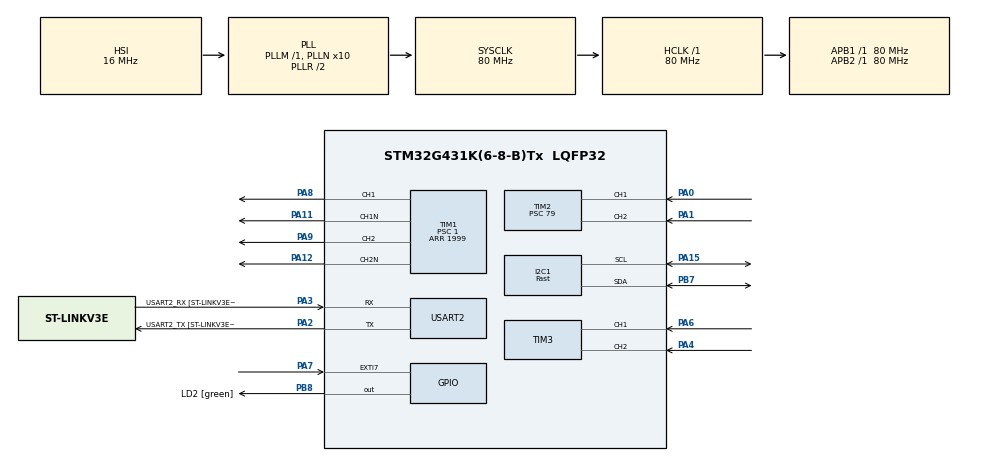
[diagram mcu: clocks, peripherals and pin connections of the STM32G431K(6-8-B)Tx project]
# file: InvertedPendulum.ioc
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I2C1.CustomTiming=Disabled
I2C1.I2C_Speed_Mode=I2C_Fast
I2C1.Timing=0x00702991
Mcu.Family=STM32G4
Mcu.Name=STM32G431K(6-8-B)Tx
Mcu.Package=LQFP32
NVIC.EXTI9_5_IRQn=true\:0\:0\:false\:false\:true\:true\:true\:true
NVIC.PriorityGroup=NVIC_PRIORITYGROUP_4
NVIC.TIM1_TRG_COM_TIM17_IRQn=true\:0\:0\:false\:false\:true\:true\:true\:true
NVIC.TIM1_UP_TIM16_IRQn=true\:0\:0\:false\:false\:true\:true\:true\:true
PA0.Signal=S_TIM2_CH1
PA1.Signal=S_TIM2_CH2
PA11.Mode=PWM Generation1 CH1 CH1N
PA11.Signal=TIM1_CH1N
PA12.Mode=PWM Generation2 CH2 CH2N
PA12.Signal=TIM1_CH2N
PA13.GPIO_Label=T_SWDIO
PA13.Mode=Serial_Wire
PA13.Signal=SYS_JTMS-SWDIO
PA14.GPIO_Label=T_SWCLK
PA14.Mode=Serial_Wire
PA14.Signal=SYS_JTCK-SWCLK
PA15.Mode=I2C
PA15.Signal=I2C1_SCL
PA2.GPIO_Label=USART2_TX [ST-LINKV3E_VCP_RX]
PA2.Mode=Asynchronous
PA2.Signal=USART2_TX
PA3.GPIO_Label=USART2_RX [ST-LINKV3E_VCP_TX]
PA3.Mode=Asynchronous
PA3.Signal=USART2_RX
PA4.Signal=S_TIM3_CH2
PA6.Signal=S_TIM3_CH1
PA7.Signal=GPXTI7
PA8.Signal=S_TIM1_CH1
PA9.Signal=S_TIM1_CH2
PB7.Mode=I2C
PB7.Signal=I2C1_SDA
PB8-BOOT0.GPIO_Label=LD2 [green]
PB8-BOOT0.Signal=GPIO_Output
ProjectManager.HeapSize=0x200
ProjectManager.StackSize=0x400
ProjectManager.TargetToolchain=STM32CubeIDE
RCC.ADC12Freq_Value=80000000
RCC.AHBFreq_Value=80000000
RCC.APB1Freq_Value=80000000
RCC.APB1TimFreq_Value=80000000
RCC.APB2Freq_Value=80000000
RCC.APB2TimFreq_Value=80000000
RCC.CortexFreq_Value=80000000
RCC.EXTERNAL_CLOCK_VALUE=12288000
RCC.HCLKFreq_Value=80000000
RCC.HSE_VALUE=8000000
RCC.HSI48_VALUE=48000000
RCC.HSI_VALUE=16000000
RCC.LSE_VALUE=32768
RCC.PLLN=10
RCC.SYSCLKFreq_VALUE=80000000
RCC.SYSCLKSource=RCC_SYSCLKSOURCE_PLLCLK
RCC.USBFreq_Value=80000000
RCC.VCOOutputFreq_Value=160000000
SH.S_TIM1_CH1.0=TIM1_CH1,PWM Generation1 CH1 CH1N
SH.S_TIM1_CH2.0=TIM1_CH2,PWM Generation2 CH2 CH2N
SH.S_TIM2_CH1.0=TIM2_CH1,Encoder_Interface
SH.S_TIM2_CH2.0=TIM2_CH2,Encoder_Interface
SH.S_TIM3_CH1.0=TIM3_CH1,Encoder_Interface
SH.S_TIM3_CH2.0=TIM3_CH2,Encoder_Interface
TIM1.AsymmetricalDeadTime=ENABLE
TIM1.Channel-PWM\ Generation1\ CH1\ CH1N=TIM_CHANNEL_1
TIM1.Channel-PWM\ Generation2\ CH2\ CH2N=TIM_CHANNEL_2
TIM1.FallingDeadTime=5
TIM1.OCMode_PWM-PWM\ Generation1\ CH1\ CH1N=TIM_OCMODE_ASSYMETRIC_PWM1
TIM1.OCMode_PWM-PWM\ Generation2\ CH2\ CH2N=TIM_OCMODE_ASSYMETRIC_PWM1
TIM1.PeriodNoDither=1999
TIM1.Prescaler=1
TIM16.PeriodNoDither=999
TIM16.Prescaler=799
TIM17.PeriodNoDither=999
TIM17.Prescaler=79
TIM2.EncoderMode=TIM_ENCODERMODE_TI12
TIM2.PeriodNoDither=999
TIM2.Prescaler=79
TIM3.EncoderMode=TIM_ENCODERMODE_TI12
USART2.VirtualMode-Asynchronous=VM_ASYNC
USART2.WordLength=WORDLENGTH_8B
VP_TIM16_VS_ClockSourceINT.Mode=Enable_Timer
VP_TIM17_VS_ClockSourceINT.Mode=Enable_Timer
VP_TIM1_VS_ClockSourceINT.Mode=Internal
board=NUCLEO-G431KB

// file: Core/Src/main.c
/* USER CODE BEGIN Header */
/**
  ******************************************************************************
  * @file           : main.c
  * @brief          : Main program body
  ******************************************************************************
  * @attention
  *
  * Copyright (c) 2023 STMicroelectronics.
  * All rights reserved.
  *
  * This software is licensed under terms that can be found in the LICENSE file
  * in the root directory of this software component.
  * If no LICENSE file comes with this software, it is provided AS-IS.
  *
  ******************************************************************************
  */
/* USER CODE END Header */
#include "main.h"

/* USER CODE BEGIN Includes */
#include <stdio.h>

/* USER CODE END Includes */

I2C_HandleTypeDef hi2c1;

TIM_HandleTypeDef htim1;
TIM_HandleTypeDef htim2;
TIM_HandleTypeDef htim3;
TIM_HandleTypeDef htim16;
TIM_HandleTypeDef htim17;

UART_HandleTypeDef huart2;

void SystemClock_Config(void);
static void MX_GPIO_Init(void);
static void MX_USART2_UART_Init(void);
static void MX_TIM2_Init(void);
static void MX_TIM3_Init(void);
static void MX_TIM1_Init(void);
static void MX_TIM17_Init(void);
static void MX_I2C1_Init(void);
static void MX_TIM16_Init(void);

/* USER CODE BEGIN 0 */
int _write(int file, char *ptr, int len)
{
	HAL_UART_Transmit(&huart2, (uint8_t *)ptr, len, 10);
	return len;
}

int16_t read_encoder_value(TIM_TypeDef TIM)
{
	uint16_t enc_buff = TIM->CNT;
	TIM->CNT = 0;
	return (int16_t)enc_buff;
}

/* USER CODE END 0 */

int main(void)
{

  /* MCU Configuration--------------------------------------------------------*/

  /* Reset of all peripherals, Initializes the Flash interface and the Systick. */
  HAL_Init();

  /* Configure the system clock */
  SystemClock_Config();

  /* Initialize all configured peripherals */
  MX_GPIO_Init();
  MX_USART2_UART_Init();
  MX_TIM2_Init();
  MX_TIM3_Init();
  MX_TIM1_Init();
  MX_TIM17_Init();
  MX_I2C1_Init();
  MX_TIM16_Init();

  /* Infinite loop */
  while (1)
  {

  }
}

void SystemClock_Config(void)
{
  RCC_OscInitTypeDef RCC_OscInitStruct = {0};
  RCC_ClkInitTypeDef RCC_ClkInitStruct = {0};

  /** Configure the main internal regulator output voltage
  */
  HAL_PWREx_ControlVoltageScaling(PWR_REGULATOR_VOLTAGE_SCALE1);

  /** Initializes the RCC Oscillators according to the specified parameters
  * in the RCC_OscInitTypeDef structure.
  */
  RCC_OscInitStruct.OscillatorType = RCC_OSCILLATORTYPE_HSI;
  RCC_OscInitStruct.HSIState = RCC_HSI_ON;
  RCC_OscInitStruct.HSICalibrationValue = RCC_HSICALIBRATION_DEFAULT;
  RCC_OscInitStruct.PLL.PLLState = RCC_PLL_ON;
  RCC_OscInitStruct.PLL.PLLSource = RCC_PLLSOURCE_HSI;
  RCC_OscInitStruct.PLL.PLLM = RCC_PLLM_DIV1;
  RCC_OscInitStruct.PLL.PLLN = 10;
  RCC_OscInitStruct.PLL.PLLP = RCC_PLLP_DIV2;
  RCC_OscInitStruct.PLL.PLLQ = RCC_PLLQ_DIV2;
  RCC_OscInitStruct.PLL.PLLR = RCC_PLLR_DIV2;
  if (HAL_RCC_OscConfig(&RCC_OscInitStruct) != HAL_OK)
  {
    Error_Handler();
  }

  /** Initializes the CPU, AHB and APB buses clocks
  */
  RCC_ClkInitStruct.ClockType = RCC_CLOCKTYPE_HCLK|RCC_CLOCKTYPE_SYSCLK
                              |RCC_CLOCKTYPE_PCLK1|RCC_CLOCKTYPE_PCLK2;
  RCC_ClkInitStruct.SYSCLKSource = RCC_SYSCLKSOURCE_PLLCLK;
  RCC_ClkInitStruct.AHBCLKDivider = RCC_SYSCLK_DIV1;
  RCC_ClkInitStruct.APB1CLKDivider = RCC_HCLK_DIV1;
  RCC_ClkInitStruct.APB2CLKDivider = RCC_HCLK_DIV1;

  if (HAL_RCC_ClockConfig(&RCC_ClkInitStruct, FLASH_LATENCY_2) != HAL_OK)
  {
    Error_Handler();
  }
}

static void MX_I2C1_Init(void)
{

  hi2c1.Instance = I2C1;
  hi2c1.Init.Timing = 0x00702991;
  hi2c1.Init.OwnAddress1 = 0;
  hi2c1.Init.AddressingMode = I2C_ADDRESSINGMODE_7BIT;
  hi2c1.Init.DualAddressMode = I2C_DUALADDRESS_DISABLE;
  hi2c1.Init.OwnAddress2 = 0;
  hi2c1.Init.OwnAddress2Masks = I2C_OA2_NOMASK;
  hi2c1.Init.GeneralCallMode = I2C_GENERALCALL_DISABLE;
  hi2c1.Init.NoStretchMode = I2C_NOSTRETCH_DISABLE;
  if (HAL_I2C_Init(&hi2c1) != HAL_OK)
  {
    Error_Handler();
  }

  /** Configure Analogue filter
  */
  if (HAL_I2CEx_ConfigAnalogFilter(&hi2c1, I2C_ANALOGFILTER_ENABLE) != HAL_OK)
  {
    Error_Handler();
  }

  /** Configure Digital filter
  */
  if (HAL_I2CEx_ConfigDigitalFilter(&hi2c1, 0) != HAL_OK)
  {
    Error_Handler();
  }

}

static void MX_TIM1_Init(void)
{

  TIM_ClockConfigTypeDef sClockSourceConfig = {0};
  TIM_MasterConfigTypeDef sMasterConfig = {0};
  TIM_OC_InitTypeDef sConfigOC = {0};
  TIM_BreakDeadTimeConfigTypeDef sBreakDeadTimeConfig = {0};

  htim1.Instance = TIM1;
  htim1.Init.Prescaler = 1;
  htim1.Init.CounterMode = TIM_COUNTERMODE_UP;
  htim1.Init.Period = 1999;
  htim1.Init.ClockDivision = TIM_CLOCKDIVISION_DIV1;
  htim1.Init.RepetitionCounter = 0;
  htim1.Init.AutoReloadPreload = TIM_AUTORELOAD_PRELOAD_DISABLE;
  if (HAL_TIM_Base_Init(&htim1) != HAL_OK)
  {
    Error_Handler();
  }
  sClockSourceConfig.ClockSource = TIM_CLOCKSOURCE_INTERNAL;
  if (HAL_TIM_ConfigClockSource(&htim1, &sClockSourceConfig) != HAL_OK)
  {
    Error_Handler();
  }
  if (HAL_TIM_PWM_Init(&htim1) != HAL_OK)
  {
    Error_Handler();
  }
  sMasterConfig.MasterOutputTrigger = TIM_TRGO_RESET;
  sMasterConfig.MasterOutputTrigger2 = TIM_TRGO2_RESET;
  sMasterConfig.MasterSlaveMode = TIM_MASTERSLAVEMODE_DISABLE;
  if (HAL_TIMEx_MasterConfigSynchronization(&htim1, &sMasterConfig) != HAL_OK)
  {
    Error_Handler();
  }
  sConfigOC.OCMode = TIM_OCMODE_ASSYMETRIC_PWM1;
  sConfigOC.Pulse = 0;
  sConfigOC.OCPolarity = TIM_OCPOLARITY_HIGH;
  sConfigOC.OCNPolarity = TIM_OCNPOLARITY_HIGH;
  sConfigOC.OCFastMode = TIM_OCFAST_DISABLE;
  sConfigOC.OCIdleState = TIM_OCIDLESTATE_RESET;
  sConfigOC.OCNIdleState = TIM_OCNIDLESTATE_RESET;
  if (HAL_TIM_PWM_ConfigChannel(&htim1, &sConfigOC, TIM_CHANNEL_1) != HAL_OK)
  {
    Error_Handler();
  }
  if (HAL_TIM_PWM_ConfigChannel(&htim1, &sConfigOC, TIM_CHANNEL_2) != HAL_OK)
  {
    Error_Handler();
  }
  HAL_TIMEx_ConfigAsymmetricalDeadTime(&htim1, 5);
  HAL_TIMEx_EnableAsymmetricalDeadTime(&htim1);
  sBreakDeadTimeConfig.OffStateRunMode = TIM_OSSR_DISABLE;
  sBreakDeadTimeConfig.OffStateIDLEMode = TIM_OSSI_DISABLE;
  sBreakDeadTimeConfig.LockLevel = TIM_LOCKLEVEL_OFF;
  sBreakDeadTimeConfig.DeadTime = 0;
  sBreakDeadTimeConfig.BreakState = TIM_BREAK_DISABLE;
  sBreakDeadTimeConfig.BreakPolarity = TIM_BREAKPOLARITY_HIGH;
  sBreakDeadTimeConfig.BreakFilter = 0;
  sBreakDeadTimeConfig.BreakAFMode = TIM_BREAK_AFMODE_INPUT;
  sBreakDeadTimeConfig.Break2State = TIM_BREAK2_DISABLE;
  sBreakDeadTimeConfig.Break2Polarity = TIM_BREAK2POLARITY_HIGH;
  sBreakDeadTimeConfig.Break2Filter = 0;
  sBreakDeadTimeConfig.Break2AFMode = TIM_BREAK_AFMODE_INPUT;
  sBreakDeadTimeConfig.AutomaticOutput = TIM_AUTOMATICOUTPUT_DISABLE;
  if (HAL_TIMEx_ConfigBreakDeadTime(&htim1, &sBreakDeadTimeConfig) != HAL_OK)
  {
    Error_Handler();
  }
  HAL_TIM_MspPostInit(&htim1);

}

static void MX_TIM2_Init(void)
{

  TIM_Encoder_InitTypeDef sConfig = {0};
  TIM_MasterConfigTypeDef sMasterConfig = {0};

  htim2.Instance = TIM2;
  htim2.Init.Prescaler = 79;
  htim2.Init.CounterMode = TIM_COUNTERMODE_UP;
  htim2.Init.Period = 999;
  htim2.Init.ClockDivision = TIM_CLOCKDIVISION_DIV1;
  htim2.Init.AutoReloadPreload = TIM_AUTORELOAD_PRELOAD_DISABLE;
  sConfig.EncoderMode = TIM_ENCODERMODE_TI12;
  sConfig.IC1Polarity = TIM_ICPOLARITY_RISING;
  sConfig.IC1Selection = TIM_ICSELECTION_DIRECTTI;
  sConfig.IC1Prescaler = TIM_ICPSC_DIV1;
  sConfig.IC1Filter = 0;
  sConfig.IC2Polarity = TIM_ICPOLARITY_RISING;
  sConfig.IC2Selection = TIM_ICSELECTION_DIRECTTI;
  sConfig.IC2Prescaler = TIM_ICPSC_DIV1;
  sConfig.IC2Filter = 0;
  if (HAL_TIM_Encoder_Init(&htim2, &sConfig) != HAL_OK)
  {
    Error_Handler();
  }
  sMasterConfig.MasterOutputTrigger = TIM_TRGO_RESET;
  sMasterConfig.MasterSlaveMode = TIM_MASTERSLAVEMODE_DISABLE;
  if (HAL_TIMEx_MasterConfigSynchronization(&htim2, &sMasterConfig) != HAL_OK)
  {
    Error_Handler();
  }

}

static void MX_TIM3_Init(void)
{

  TIM_Encoder_InitTypeDef sConfig = {0};
  TIM_MasterConfigTypeDef sMasterConfig = {0};

  htim3.Instance = TIM3;
  htim3.Init.Prescaler = 0;
  htim3.Init.CounterMode = TIM_COUNTERMODE_UP;
  htim3.Init.Period = 65535;
  htim3.Init.ClockDivision = TIM_CLOCKDIVISION_DIV1;
  htim3.Init.AutoReloadPreload = TIM_AUTORELOAD_PRELOAD_DISABLE;
  sConfig.EncoderMode = TIM_ENCODERMODE_TI12;
  sConfig.IC1Polarity = TIM_ICPOLARITY_RISING;
  sConfig.IC1Selection = TIM_ICSELECTION_DIRECTTI;
  sConfig.IC1Prescaler = TIM_ICPSC_DIV1;
  sConfig.IC1Filter = 0;
  sConfig.IC2Polarity = TIM_ICPOLARITY_RISING;
  sConfig.IC2Selection = TIM_ICSELECTION_DIRECTTI;
  sConfig.IC2Prescaler = TIM_ICPSC_DIV1;
  sConfig.IC2Filter = 0;
  if (HAL_TIM_Encoder_Init(&htim3, &sConfig) != HAL_OK)
  {
    Error_Handler();
  }
  sMasterConfig.MasterOutputTrigger = TIM_TRGO_RESET;
  sMasterConfig.MasterSlaveMode = TIM_MASTERSLAVEMODE_DISABLE;
  if (HAL_TIMEx_MasterConfigSynchronization(&htim3, &sMasterConfig) != HAL_OK)
  {
    Error_Handler();
  }

}

static void MX_TIM16_Init(void)
{

  htim16.Instance = TIM16;
  htim16.Init.Prescaler = 799;
  htim16.Init.CounterMode = TIM_COUNTERMODE_UP;
  htim16.Init.Period = 999;
  htim16.Init.ClockDivision = TIM_CLOCKDIVISION_DIV1;
  htim16.Init.RepetitionCounter = 0;
  htim16.Init.AutoReloadPreload = TIM_AUTORELOAD_PRELOAD_DISABLE;
  if (HAL_TIM_Base_Init(&htim16) != HAL_OK)
  {
    Error_Handler();
  }

}

static void MX_TIM17_Init(void)
{

  htim17.Instance = TIM17;
  htim17.Init.Prescaler = 79;
  htim17.Init.CounterMode = TIM_COUNTERMODE_UP;
  htim17.Init.Period = 999;
  htim17.Init.ClockDivision = TIM_CLOCKDIVISION_DIV1;
  htim17.Init.RepetitionCounter = 0;
  htim17.Init.AutoReloadPreload = TIM_AUTORELOAD_PRELOAD_DISABLE;
  if (HAL_TIM_Base_Init(&htim17) != HAL_OK)
  {
    Error_Handler();
  }

}

static void MX_USART2_UART_Init(void)
{

  huart2.Instance = USART2;
  huart2.Init.BaudRate = 115200;
  huart2.Init.WordLength = UART_WORDLENGTH_8B;
  huart2.Init.StopBits = UART_STOPBITS_1;
  huart2.Init.Parity = UART_PARITY_NONE;
  huart2.Init.Mode = UART_MODE_TX_RX;
  huart2.Init.HwFlowCtl = UART_HWCONTROL_NONE;
  huart2.Init.OverSampling = UART_OVERSAMPLING_16;
  huart2.Init.OneBitSampling = UART_ONE_BIT_SAMPLE_DISABLE;
  huart2.Init.ClockPrescaler = UART_PRESCALER_DIV1;
  huart2.AdvancedInit.AdvFeatureInit = UART_ADVFEATURE_NO_INIT;
  if (HAL_UART_Init(&huart2) != HAL_OK)
  {
    Error_Handler();
  }
  if (HAL_UARTEx_SetTxFifoThreshold(&huart2, UART_TXFIFO_THRESHOLD_1_8) != HAL_OK)
  {
    Error_Handler();
  }
  if (HAL_UARTEx_SetRxFifoThreshold(&huart2, UART_RXFIFO_THRESHOLD_1_8) != HAL_OK)
  {
    Error_Handler();
  }
  if (HAL_UARTEx_DisableFifoMode(&huart2) != HAL_OK)
  {
    Error_Handler();
  }

}

static void MX_GPIO_Init(void)
{
  GPIO_InitTypeDef GPIO_InitStruct = {0};

  /* GPIO Ports Clock Enable */
  __HAL_RCC_GPIOA_CLK_ENABLE();
  __HAL_RCC_GPIOB_CLK_ENABLE();

  /*Configure GPIO pin Output Level */
  HAL_GPIO_WritePin(LD2_GPIO_Port, LD2_Pin, GPIO_PIN_RESET);

  /*Configure GPIO pin : PA7 */
  GPIO_InitStruct.Pin = GPIO_PIN_7;
  GPIO_InitStruct.Mode = GPIO_MODE_IT_RISING;
  GPIO_InitStruct.Pull = GPIO_NOPULL;
  HAL_GPIO_Init(GPIOA, &GPIO_InitStruct);

  /*Configure GPIO pin : LD2_Pin */
  GPIO_InitStruct.Pin = LD2_Pin;
  GPIO_InitStruct.Mode = GPIO_MODE_OUTPUT_PP;
  GPIO_InitStruct.Pull = GPIO_NOPULL;
  GPIO_InitStruct.Speed = GPIO_SPEED_FREQ_LOW;
  HAL_GPIO_Init(LD2_GPIO_Port, &GPIO_InitStruct);

  /* EXTI interrupt init*/
  HAL_NVIC_SetPriority(EXTI9_5_IRQn, 0, 0);
  HAL_NVIC_EnableIRQ(EXTI9_5_IRQn);

}

void Error_Handler(void)
{
  __disable_irq();
  while (1)
  {
  }
}
